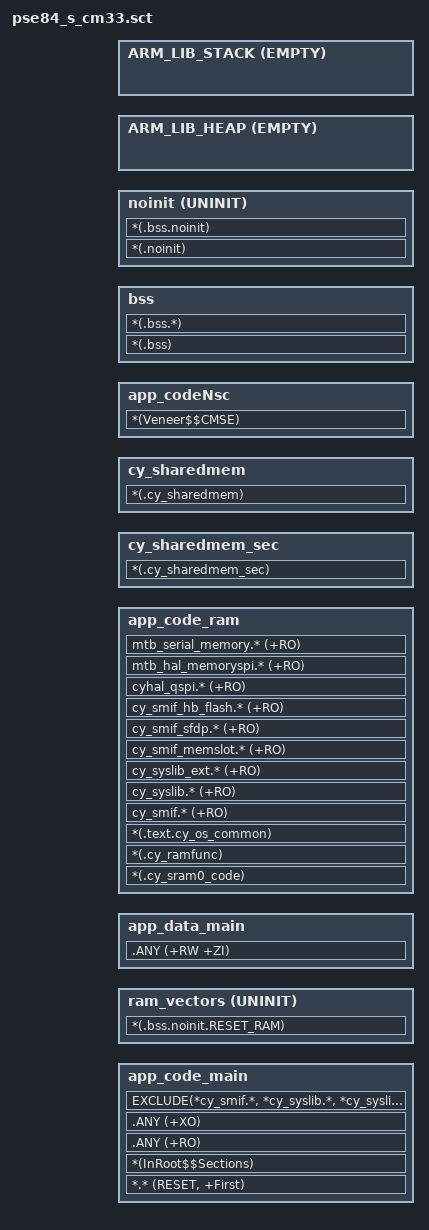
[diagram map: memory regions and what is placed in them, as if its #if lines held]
#! armclang -E --target=arm-arm-none-eabi -mcpu=cortex-m33 -xc
; command above MUST be in first line (no comment above!)
/***************************************************************************//**
* \file pse84_s_cm33.sct
* \version 1.0.0
*
* scatter file for the armclang C compiler.
*
* The main purpose of this file is to describe how the sections in the
* input files should be mapped into the output file, and to control the memory
* layout of the output file.
*
* \note The entry point location starts at 0x14000000. The valid
* application image should be placed there.
*
* \note The linker files included with the PDL template projects must be generic
* and handle all common use cases. Your project may not use every section
* defined in the linker files. In that case you may see warnings during the
* build process. In your project, you can simply comment out or remove the
* relevant code in the linker file.
*
********************************************************************************
* \copyright
* Copyright (c) (2020-2025), Cypress Semiconductor Corporation (an Infineon company) or
* an affiliate of Cypress Semiconductor Corporation.
* SPDX-License-Identifier: Apache-2.0
*
* Licensed under the Apache License, Version 2.0 (the "License");
* you may not use this file except in compliance with the License.
* You may obtain a copy of the License at
*
*     http://www.apache.org/licenses/LICENSE-2.0
*
* Unless required by applicable law or agreed to in writing, software
* distributed under the License is distributed on an "AS IS" BASIS,
* WITHOUT WARRANTIES OR CONDITIONS OF ANY KIND, either express or implied.
* See the License for the specific language governing permissions and
* limitations under the License.
*******************************************************************************/

/* Include the device memory definitions generated by the Device Configurator */
#include "../../config/GeneratedSource/cymem_armlink_CM33_0_S.sct"

/* Define the stack size for the application */
/* To set stack size in application add makefile ldflags: --predefine="-DAPP_MSP_STACK_SIZE=0x2000" */
#ifdef APP_MSP_STACK_SIZE
#define __STACK_SIZE    APP_MSP_STACK_SIZE
#else
#define __STACK_SIZE    0x00000800
#endif

/* User Stack & Heap boundary definition */
/* Place the top of the stack at the end of the m33s_data_S */
#define __STACK_TOP    (CYMEM_CM33_0_S_m33s_data_S_START + CYMEM_CM33_0_S_m33s_data_SIZE)
/* Position the beginning of the heap right after the noinit ER, ensuring an 8-byte alignment */
#define __HEAP_BASE    AlignExpr(ImageLimit(noinit), 8)
/* The heap extends to the stack */
#define __HEAP_SIZE    (__STACK_TOP - __STACK_SIZE - __HEAP_BASE)

/* Device definitions */
#define VECTORS_ALIGNMENT 1024

/* The size of the MCU boot header area at the start of FLASH */
#define MCUBOOT_HEADER_SIZE  0x400

/* The start address and size of shared memory sub-block in shared memory region for the current core
 * The approach is to have an equal sub-block for each core to avoid shared objects to be overlapped.
 * Default configuration: A sub-block for CM33_S shared data will be 1st.
 */
#define CORE_SYSTEM_SHARED_MEM_SIZE    (CYMEM_CM33_0_S_m33_m55_system_shared_SIZE / 3)
#define CORE_SYSTEM_SHARED_MEM_START   (CYMEM_CM33_0_S_m33_m55_system_shared_S_START)

/* Serial Memory Interface block #0 memory #1, 16 MB */
LR_XIP_PORT0 (CYMEM_CM33_0_S_m33s_nvm_C_S_START + MCUBOOT_HEADER_SIZE) (CYMEM_CM33_0_S_m33s_nvm_SIZE - MCUBOOT_HEADER_SIZE)
{
  /* The execution region is designated for the main secure (S) application code for the Cortex-M33 */
  app_code_main (CYMEM_CM33_0_S_m33s_nvm_C_S_START + MCUBOOT_HEADER_SIZE) ALIGN VECTORS_ALIGNMENT (CYMEM_CM33_0_S_m33s_nvm_SIZE - MCUBOOT_HEADER_SIZE)
  {
    *.* (RESET, +First)
    *(InRoot$$Sections)
    .ANY (+RO)
    .ANY (+XO)
    EXCLUDE(*cy_smif.*, *cy_syslib.*, *cy_syslib_ext.*, *cy_smif_memslot.*, *cy_smif_sfdp.*, *cy_smif_hb_flash.*, *cyhal_qspi.*, *mtb_hal_memoryspi.*, *mtb_serial_memory.*)
  }

  /* A region for the vector table */
  ram_vectors AlignExpr(CYMEM_CM33_0_S_m33s_data_S_START, VECTORS_ALIGNMENT) ALIGN VECTORS_ALIGNMENT UNINIT CYMEM_CM33_0_S_m33s_data_SIZE
  {
    *(.bss.noinit.RESET_RAM)
  }

  /* The execution region for initialized data memory */
  app_data_main AlignExpr(ImageLimit(ram_vectors), 4) ALIGN 4 CYMEM_CM33_0_S_m33s_data_SIZE
  {
    .ANY (+RW +ZI)
  }

  /* The execution region for performance-sensitive or critical functions that need to be executed in SRAM */
  app_code_ram CYMEM_CM33_0_S_m33s_code_S_START ALIGN 4 CYMEM_CM33_0_S_m33s_code_SIZE
  {
    *(.cy_sram0_code)
    *(.cy_ramfunc)
    *(.text.cy_os_common)
    cy_smif.* (+RO)
    cy_syslib.* (+RO)
    cy_syslib_ext.* (+RO)
    cy_smif_memslot.* (+RO)
    cy_smif_sfdp.* (+RO)
    cy_smif_hb_flash.* (+RO)
    cyhal_qspi.* (+RO)
    mtb_hal_memoryspi.* (+RO)
    mtb_serial_memory.* (+RO)
  }

  /* A region for secure shared RAM memory */
  cy_sharedmem_sec CYMEM_CM33_0_S_m33s_system_shared_S_START CYMEM_CM33_0_S_m33s_system_shared_SIZE
  {
    *(.cy_sharedmem_sec)
  }

  /* A region for public shared RAM memory */
  cy_sharedmem CORE_SYSTEM_SHARED_MEM_START ALIGN 32 CORE_SYSTEM_SHARED_MEM_SIZE
  {
    *(.cy_sharedmem)
  }
}

LR_XIP_PORT0_SG CYMEM_CM33_0_S_m33_nsc_C_S_START CYMEM_CM33_0_S_m33_nsc_SIZE
{
  /* An execution region for the veneer code of Secure APIs */
  app_codeNsc CYMEM_CM33_0_S_m33_nsc_C_S_START CYMEM_CM33_0_S_m33_nsc_SIZE
  {
    *(Veneer$$CMSE)
  }
}

/* SRAM, 1 MB */
/* Note. This load region must not contain any loadable data; only UNINIT or BSS execution regions are allowed */
LR_SRAM CYMEM_CM33_0_S_m33s_data_S_START CYMEM_CM33_0_S_m33s_data_SIZE
{

  /* A section for non-initialized data memory */
  bss AlignExpr(ImageLimit(app_data_main), 4) ALIGN 4 (CYMEM_CM33_0_S_m33s_data_SIZE - AlignExpr(ImageLength(ram_vectors), VECTORS_ALIGNMENT) - AlignExpr(ImageLength(app_data_main), 4))
  {
    *(.bss)
    *(.bss.*)
  }

  /* A region for variables that should not be initialized during the device startup */
  noinit AlignExpr(ImageLimit(bss), 4) ALIGN 4 UNINIT (CYMEM_CM33_0_S_m33s_data_SIZE - AlignExpr(ImageLength(ram_vectors), VECTORS_ALIGNMENT) - AlignExpr(ImageLength(app_data_main), 4) - AlignExpr(ImageLength(bss), 4))
  {
    *(.noinit)
    *(.bss.noinit)
  }

  /* A region for the heap memory */
  ARM_LIB_HEAP __HEAP_BASE EMPTY __HEAP_SIZE
  {
  }

  /* A region for stack */
  ARM_LIB_STACK __STACK_TOP EMPTY -__STACK_SIZE
  {
  }
}
